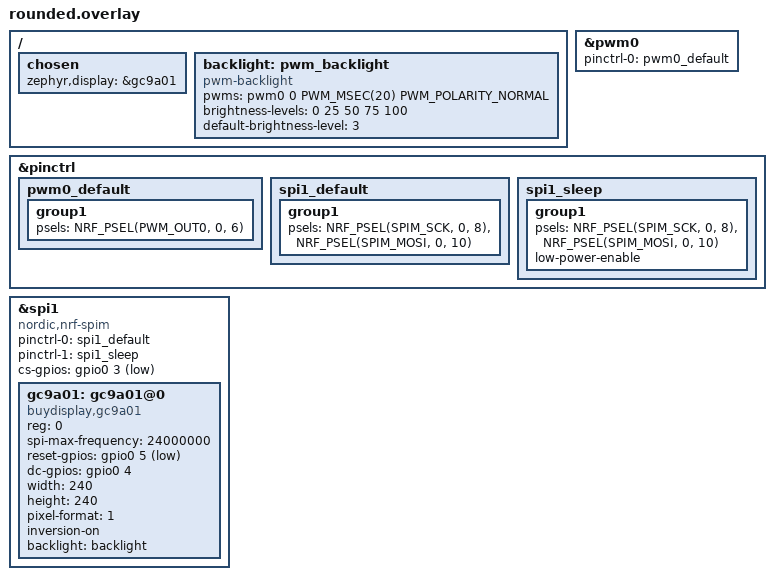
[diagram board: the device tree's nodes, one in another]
/*
 * rounded.overlay - Device tree overlay for XIAO nRF52840 with Seeed Round Display
 * Place this file in your zmk-config/config/ directory
 */

#include <dt-bindings/zmk/matrix_transform.h>

/ {
    chosen {
        zephyr,display = &gc9a01;
    };

    // Backlight control
    backlight: pwm_backlight {
        compatible = "pwm-backlight";
        pwms = <&pwm0 0 PWM_MSEC(20) PWM_POLARITY_NORMAL>;
        brightness-levels = <0 25 50 75 100>;
        default-brightness-level = <3>; // 75% brightness
        status = "okay";
    };
};

// PWM for backlight
&pwm0 {
    status = "okay";
    pinctrl-0 = <&pwm0_default>;
    pinctrl-names = "default";
};

&pinctrl {
    // PWM pin for backlight control
    pwm0_default: pwm0_default {
        group1 {
            psels = <NRF_PSEL(PWM_OUT0, 0, 6)>; // D6
        };
    };

    // SPI pins for display
    spi1_default: spi1_default {
        group1 {
            psels = <NRF_PSEL(SPIM_SCK, 0, 8)>,   // D8 - SCK
                    <NRF_PSEL(SPIM_MOSI, 0, 10)>; // D10 - MOSI
        };
    };

    spi1_sleep: spi1_sleep {
        group1 {
            psels = <NRF_PSEL(SPIM_SCK, 0, 8)>,
                    <NRF_PSEL(SPIM_MOSI, 0, 10)>;
            low-power-enable;
        };
    };
};

// SPI bus for the display
&spi1 {
    compatible = "nordic,nrf-spim";
    status = "okay";
    
    pinctrl-0 = <&spi1_default>;
    pinctrl-1 = <&spi1_sleep>;
    pinctrl-names = "default", "sleep";
    
    cs-gpios = <&gpio0 3 GPIO_ACTIVE_LOW>; // D3

    gc9a01: gc9a01@0 {
        compatible = "buydisplay,gc9a01";
        status = "okay";
        reg = <0>;
        spi-max-frequency = <24000000>; // 24MHz for stability
        
        // Control pins
        reset-gpios = <&gpio0 5 GPIO_ACTIVE_LOW>;   // D5
        dc-gpios = <&gpio0 4 GPIO_ACTIVE_HIGH>;     // D4
        
        // Display properties
        width = <240>;
        height = <240>;
        
        // Format and inversion
        pixel-format = <1>; // RGB565
        inversion-on;
        
        // Backlight control
        backlight = <&backlight>;
    };
};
